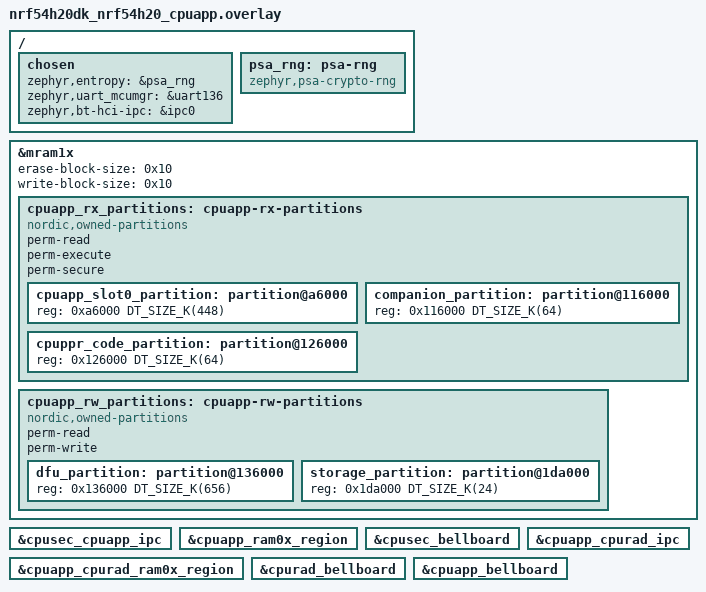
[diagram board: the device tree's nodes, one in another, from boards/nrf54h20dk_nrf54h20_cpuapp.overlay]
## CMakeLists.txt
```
#
# Copyright (c) 2023 Nordic Semiconductor ASA
#
# SPDX-License-Identifier: LicenseRef-Nordic-5-Clause
#

cmake_minimum_required(VERSION 3.13.1)

find_package(Zephyr REQUIRED HINTS $ENV{ZEPHYR_BASE})

project(suit_smp_transfer)

target_sources(app PRIVATE src/main.c)

# This project uses orginal sdk-zephyr C source code
target_include_directories(app PRIVATE $ENV{ZEPHYR_BASE}/samples/subsys/mgmt/mcumgr/smp_svr/src)
target_sources_ifdef(CONFIG_MCUMGR_TRANSPORT_BT app PRIVATE $ENV{ZEPHYR_BASE}/samples/subsys/mgmt/mcumgr/smp_svr/src/bluetooth.c)
```

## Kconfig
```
#
# Copyright (c) 2023 Nordic Semiconductor ASA
#
# SPDX-License-Identifier: LicenseRef-Nordic-5-Clause
#

config N_BLINKS
	int "Number of fast blinks"
	default 1

source "Kconfig.zephyr"
```

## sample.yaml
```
#
# Copyright (c) 2023 Nordic Semiconductor ASA
#
# SPDX-License-Identifier: LicenseRef-Nordic-5-Clause
#

sample:
  name: SUIT update through SMP sample
  description: Sample application that updates firmware using SUIT and SMP protocol
common:
  platform_allow: nrf54h20dk/nrf54h20/cpuapp
  build_only: true
  sysbuild: true
tests:
  sample.suit.smp_transfer:
    tags:
      - suit
      - ci_samples_suit
  sample.suit.smp_transfer.bt:
    extra_args:
      - FILE_SUFFIX=bt
    tags:
      - suit
      - bluetooth
      - ci_samples_suit
  sample.suit.smp_transfer.full_processing:
    extra_configs:
      - CONFIG_SUIT_DFU_CANDIDATE_PROCESSING_FULL=y
    tags:
      - suit
      - ci_samples_suit
  sample.suit.smp_transfer.full_processing.bt:
    extra_args:
      - FILE_SUFFIX=bt
    extra_configs:
      - CONFIG_SUIT_DFU_CANDIDATE_PROCESSING_FULL=y
    tags:
      - suit
      - bluetooth
      - ci_samples_suit
  sample.suit.smp_transfer.full_processing.extflash:
    extra_args:
      - EXTRA_DTC_OVERLAY_FILE="boards/nrf54h20dk_nrf54h20_cpuapp_extflash.overlay"
      - SB_CONFIG_SUIT_BUILD_FLASH_COMPANION=y
      # Workaround for sample.yaml - problems with strings. In the command line simply use:
      # -D'SB_CONFIG_SUIT_ENVELOPE_ROOT_TEMPLATE_FILENAME="root_with_binary_nordic_top_extflash.yaml.jinja2"'
      - SB_EXTRA_CONF_FILE="sysbuild_extflash_template.conf"
    extra_configs:
      - CONFIG_SUIT_ENVELOPE_TEMPLATE_FILENAME="app_envelope_extflash.yaml.jinja2"
      - CONFIG_SUIT_STREAM_SOURCE_FLASH=y
      - CONFIG_SUIT_DFU_CANDIDATE_PROCESSING_FULL=y
    tags:
      - suit
      - ci_samples_suit
  sample.suit.smp_transfer.recovery:
    extra_args:
      - FILE_SUFFIX=bt
      - SB_CONFIG_SUIT_BUILD_RECOVERY=y
    tags:
      - suit
      - bluetooth
      - ci_samples_suit
  sample.suit.smp_transfer.full_processing.extflash.bt:
    extra_args:
      - FILE_SUFFIX=bt
      - EXTRA_DTC_OVERLAY_FILE="boards/nrf54h20dk_nrf54h20_cpuapp_extflash.overlay"
      - SB_CONFIG_SUIT_BUILD_FLASH_COMPANION=y
      - SB_CONFIG_SUIT_BUILD_RECOVERY=y
      - recovery_TARGET_EXTRA_DTC_OVERLAY_FILE="boards/nrf54h20dk_nrf54h20_cpuapp_extflash.overlay"
      # Workaround for sample.yaml - problems with strings. In the command line simply use:
      # -D'SB_CONFIG_SUIT_ENVELOPE_ROOT_TEMPLATE_FILENAME="root_with_binary_nordic_top_extflash.yaml.jinja2"'
      - SB_EXTRA_CONF_FILE="sysbuild_extflash_template.conf"
      # Workaround for sample.yaml (part also in sysbuild.cmake), in the command line simply use:
      # -D'hci_ipc_CONFIG_SUIT_ENVELOPE_TEMPLATE_FILENAME="rad_envelope_extflash.yaml.jinja2"'
      - hci_ipc_TARGET_EXTRA_CONF_FILE="sysbuild/hci_ipc_extflash_template.conf"
    extra_configs:
      - CONFIG_SUIT_ENVELOPE_TEMPLATE_FILENAME="app_envelope_extflash.yaml.jinja2"
      - CONFIG_SUIT_STREAM_SOURCE_FLASH=y
      - CONFIG_SUIT_DFU_CANDIDATE_PROCESSING_FULL=y
    tags:
      - suit
      - bluetooth
      - ci_samples_suit
  sample.suit.smp_transfer.cache_push.extflash:
    extra_args:
      - EXTRA_DTC_OVERLAY_FILE="boards/nrf54h20dk_nrf54h20_cpuapp_extflash.overlay"
      - SUIT_DFU_CACHE_PARTITION_1_EB_SIZE=4096
      - SB_CONFIG_SUIT_BUILD_FLASH_COMPANION=y
      # Workaround for sample.yaml - problems with strings. In the command line simply use:
      # -D'SB_CONFIG_SUIT_ENVELOPE_ROOT_TEMPLATE_FILENAME="root_with_binary_nordic_top_extflash.yaml.jinja2"'
      - SB_EXTRA_CONF_FILE="sysbuild_extflash_template.conf"
    extra_configs:
      - CONFIG_SUIT_ENVELOPE_TEMPLATE_FILENAME="app_envelope_extflash.yaml.jinja2"
      - CONFIG_SUIT_DFU_CACHE_EXTRACT_IMAGE=y
      - CONFIG_SUIT_DFU_CANDIDATE_PROCESSING_PUSH_TO_CACHE=y
    tags:
      - suit
      - ci_samples_suit
  sample.suit.smp_transfer.cache_push.extflash.bt:
    extra_args:
      - FILE_SUFFIX=bt
      - EXTRA_DTC_OVERLAY_FILE="boards/nrf54h20dk_nrf54h20_cpuapp_extflash.overlay"
      - recovery_TARGET_EXTRA_DTC_OVERLAY_FILE="boards/nrf54h20dk_nrf54h20_cpuapp_extflash.overlay"
      - SUIT_DFU_CACHE_PARTITION_1_EB_SIZE=4096
      - SB_CONFIG_SUIT_BUILD_FLASH_COMPANION=y
      - SB_CONFIG_SUIT_BUILD_RECOVERY=y
      # Workaround for sample.yaml - problems with strings. In the command line simply use:
      # -D'SB_CONFIG_SUIT_ENVELOPE_ROOT_TEMPLATE_FILENAME="root_with_binary_nordic_top_extflash.yaml.jinja2"'
      - SB_EXTRA_CONF_FILE="sysbuild_extflash_template.conf"
      # Workaround for sample.yaml (part also in sysbuild.cmake), in the command line simply use:
      # -D'hci_ipc_CONFIG_SUIT_ENVELOPE_TEMPLATE_FILENAME="rad_envelope_extflash.yaml.jinja2"'
      - hci_ipc_TARGET_EXTRA_CONF_FILE="sysbuild/hci_ipc_extflash_template.conf"
      - hci_ipc_CONFIG_SUIT_DFU_CACHE_EXTRACT_IMAGE=y
    extra_configs:
      - CONFIG_SUIT_ENVELOPE_TEMPLATE_FILENAME="app_envelope_extflash.yaml.jinja2"
      - CONFIG_SUIT_DFU_CACHE_EXTRACT_IMAGE=y
      - CONFIG_SUIT_DFU_CANDIDATE_PROCESSING_PUSH_TO_CACHE=y
    tags:
      - suit
      - bluetooth
      - ci_samples_suit
```

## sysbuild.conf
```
#
# Copyright (c) 2024 Nordic Semiconductor ASA
#
# SPDX-License-Identifier: LicenseRef-Nordic-5-Clause
#

SB_CONFIG_SUIT_ENVELOPE=y
```

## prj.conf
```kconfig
#
# Copyright (c) 2023 Nordic Semiconductor ASA
#
# SPDX-License-Identifier: LicenseRef-Nordic-5-Clause
#

# Enable DK LED library
CONFIG_DK_LIBRARY=y

# Enable mcumgr
CONFIG_NET_BUF=y
CONFIG_ZCBOR=y
CONFIG_ZCBOR_CANONICAL=y
CONFIG_MCUMGR=y
CONFIG_MCUMGR_SMP_LEGACY_RC_BEHAVIOUR=y
CONFIG_CRC=y

# Enable SUIT services
CONFIG_SUIT=y
CONFIG_MGMT_SUITFU=y
CONFIG_FLASH=y

# Extended SUIT commands over USER group
CONFIG_MGMT_SUITFU_GRP_SUIT=y

# Enable bootloader identification within OS Management group
CONFIG_MCUMGR_GRP_OS=y
CONFIG_MCUMGR_GRP_OS_BOOTLOADER_INFO=y
CONFIG_MCUMGR_MGMT_NOTIFICATION_HOOKS=y
CONFIG_MCUMGR_GRP_OS_BOOTLOADER_INFO_HOOK=y

# For UART transport settings see: sysbuild/smp_transfer.conf
# For BLE transport settings see: sysbuild/smp_transfer_bt.conf
```

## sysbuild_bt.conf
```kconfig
#
# Copyright (c) 2024 Nordic Semiconductor ASA
#
# SPDX-License-Identifier: LicenseRef-Nordic-5-Clause
#

SB_CONFIG_SUIT_ENVELOPE=y
SB_CONFIG_NETCORE_HCI_IPC=y
```

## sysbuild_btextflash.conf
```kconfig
#
# Copyright (c) 2024 Nordic Semiconductor ASA
#
# SPDX-License-Identifier: LicenseRef-Nordic-5-Clause
#

SB_CONFIG_SUIT_ENVELOPE=y
SB_CONFIG_SUIT_BUILD_FLASH_COMPANION=y
SB_CONFIG_SUIT_ENVELOPE_ROOT_TEMPLATE="templates/extflash/root_with_binary_nordic_top.yaml.jinja2"
SB_CONFIG_NETCORE_HCI_IPC=y
```

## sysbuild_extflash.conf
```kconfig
#
# Copyright (c) 2024 Nordic Semiconductor ASA
#
# SPDX-License-Identifier: LicenseRef-Nordic-5-Clause
#

SB_CONFIG_SUIT_ENVELOPE=y
SB_CONFIG_SUIT_BUILD_FLASH_COMPANION=y
SB_CONFIG_SUIT_ENVELOPE_ROOT_TEMPLATE_FILENAME="root_with_binary_nordic_top_extflash.yaml.jinja2"
```

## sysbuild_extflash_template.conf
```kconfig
#
# Copyright (c) 2024 Nordic Semiconductor ASA
#
# SPDX-License-Identifier: LicenseRef-Nordic-5-Clause
#

SB_CONFIG_SUIT_ENVELOPE_ROOT_TEMPLATE_FILENAME="root_with_binary_nordic_top_extflash.yaml.jinja2"
```

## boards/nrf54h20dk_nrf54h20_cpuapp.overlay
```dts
/*
 * Copyright (c) 2023 Nordic Semiconductor ASA
 *
 * SPDX-License-Identifier: LicenseRef-Nordic-5-Clause
 */

/ {
	chosen {
		zephyr,entropy = &psa_rng;
		zephyr,uart_mcumgr = &uart136;
		zephyr,bt-hci-ipc = &ipc0;
	};

	psa_rng: psa-rng {
		compatible = "zephyr,psa-crypto-rng";
		status = "okay";
	};
};

/delete-node/ &cpuapp_rx_partitions;
/delete-node/ &cpuapp_rw_partitions;

&mram1x {
	erase-block-size = < 0x10 >;
	/* Hardcoded inside the soc_flash_nrf_mram.c (MRAM_WORD_SIZE) */
	write-block-size = < 0x10 >;

	cpuapp_rx_partitions: cpuapp-rx-partitions {
		compatible = "nordic,owned-partitions", "fixed-partitions";
		status = "okay";
		perm-read;
		perm-execute;
		perm-secure;
		#address-cells = <1>;
		#size-cells = <1>;

		cpuapp_slot0_partition: partition@a6000 {
			reg = <0xa6000 DT_SIZE_K(448)>;
		};

		companion_partition: partition@116000 {
			reg = <0x116000 DT_SIZE_K(64)>;
		};

		cpuppr_code_partition: partition@126000 {
			reg = <0x126000 DT_SIZE_K(64)>;
		};
	};

	cpuapp_rw_partitions: cpuapp-rw-partitions {
		compatible = "nordic,owned-partitions", "fixed-partitions";
		status = "okay";
		perm-read;
		perm-write;
		#address-cells = < 0x1 >;
		#size-cells = < 0x1 >;

		dfu_partition: partition@136000 {
			reg = < 0x136000 DT_SIZE_K(656) >;
		};

		storage_partition: partition@1da000 {
			reg = < 0x1da000 DT_SIZE_K(24) >;
		};
	};
};

&cpusec_cpuapp_ipc {
	status = "okay";
};

&cpuapp_ram0x_region {
	status = "okay";
};

&cpusec_bellboard {
	status = "okay";
};

ipc0: &cpuapp_cpurad_ipc {
	status = "okay";
};

&cpuapp_cpurad_ram0x_region {
	status = "okay";
};

&cpurad_bellboard {
	status = "okay";
};

&cpuapp_bellboard {
	status = "okay";
};
```

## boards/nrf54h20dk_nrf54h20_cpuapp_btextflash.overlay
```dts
/*
 * Copyright (c) 2024 Nordic Semiconductor ASA
 *
 * SPDX-License-Identifier: LicenseRef-Nordic-5-Clause
 */

#include "nrf54h20dk_nrf54h20_cpuapp_common.dtsi"

/ {
	chosen {
		extmem-device = &mx25uw63;
	};
};

&mx25uw63 {
	status = "okay";
	partitions {
		compatible = "fixed-partitions";
		#address-cells = <1>;
		#size-cells = <1>;

		dfu_cache_partition_1: partition@0 {
			reg = <0x0 DT_SIZE_K(1024)>;
		};
	};
};
```

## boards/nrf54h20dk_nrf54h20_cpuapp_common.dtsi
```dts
/*
 * Copyright (c) 2024 Nordic Semiconductor ASA
 *
 * SPDX-License-Identifier: LicenseRef-Nordic-5-Clause
 */

 #include "../sysbuild/nrf54h20dk_nrf54h20_memory_map.dtsi"

/ {
	chosen {
		zephyr,entropy = &psa_rng;
		zephyr,uart-mcumgr = &uart136;
		zephyr,bt-hci-ipc = &ipc0;
	};

	psa_rng: psa-rng {
		compatible = "zephyr,psa-crypto-rng";
		status = "okay";
	};
};

&cpusec_cpuapp_ipc {
	status = "okay";
};

&cpuapp_ram0x_region {
	status = "okay";
};

&cpusec_bellboard {
	status = "okay";
};

ipc0: &cpuapp_cpurad_ipc {
	status = "okay";
};

&cpurad_bellboard {
	status = "okay";
};

&cpuapp_bellboard {
	status = "okay";
};

&uart136 {
	/delete-property/ hw-flow-control;
};
```

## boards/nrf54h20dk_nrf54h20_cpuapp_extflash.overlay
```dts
/*
 * Copyright (c) 2024 Nordic Semiconductor ASA
 *
 * SPDX-License-Identifier: LicenseRef-Nordic-5-Clause
 */

/ {
	chosen {
		extmem-device = &mx25uw63;
	};
};

&mx25uw63 {
	status = "okay";
	partitions {
		compatible = "fixed-partitions";
		#address-cells = <1>;
		#size-cells = <1>;

		dfu_cache_partition_1: partition@0 {
			reg = <0x0 DT_SIZE_K(1024)>;
		};
	};
};

&cpuapp_rx_partitions {
	/delete-node/ partition@9d000;
	cpuapp_recovery_partition: partition@9d000 {
		reg = <0x9d000 DT_SIZE_K(84)>;
	};

	/delete-node/ partition@af000;
	cpuapp_recovery_rfu_partition: partition@b2000 {
		reg = <0xb2000 DT_SIZE_K(44)>;
	};

	/delete-node/ partition@bd000;
	cpuapp_slot0_partition: partition@bd000 {
		reg = <0xbd000 DT_SIZE_K(780)>;
	};
};

&cpuapp_rw_partitions {
	/delete-node/ partition@100000;
	dfu_partition: partition@180000 {
		reg = < 0x180000 DT_SIZE_K(396) >;
	};
};
```

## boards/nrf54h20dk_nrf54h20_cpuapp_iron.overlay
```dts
/*
 * Copyright (c) 2023 Nordic Semiconductor ASA
 *
 * SPDX-License-Identifier: LicenseRef-Nordic-5-Clause
 */

#include "nrf54h20dk_nrf54h20_cpuapp_common.dtsi"
```

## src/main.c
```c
/*
 * Copyright (c) 2023 Nordic Semiconductor ASA
 *
 * SPDX-License-Identifier: LicenseRef-Nordic-5-Clause
 */

#include <zephyr/kernel.h>
#include <dk_buttons_and_leds.h>
#ifdef CONFIG_MGMT_SUITFU
#include <suitfu_mgmt.h>
#endif /* CONFIG_MGMT_SUITFU */
#include <zephyr/storage/flash_map.h>
#include "common.h"

#ifdef CONFIG_SSF_SUIT_SERVICE_ENABLED
#include <sdfw/sdfw_services/suit_service.h>
#endif /* CONFIG_SSF_SUIT_SERVICE_ENABLED */

#define DFU_PARTITION_OFFSET  FIXED_PARTITION_OFFSET(dfu_partition)
#define DFU_PARTITION_SIZE    FIXED_PARTITION_SIZE(dfu_partition)
#define DFU_PARTITION_ADDRESS suit_plat_mem_nvm_ptr_get(DFU_PARTITION_OFFSET)

int main(void)
{
	int ret = dk_leds_init();

	if (ret) {
		printk("Cannot init LEDs (err: %d)\r\n", ret);
	}

	printk("Hello world from %s blinks: %d, BUILD: %s %s\r\n", CONFIG_BOARD, CONFIG_N_BLINKS,
	       __DATE__, __TIME__);

	if (IS_ENABLED(CONFIG_MCUMGR_TRANSPORT_BT)) {
		start_smp_bluetooth_adverts();
	}

	while (1) {
		for (int i = 0; i < CONFIG_N_BLINKS; i++) {
			dk_set_led_on(DK_LED1);
			k_msleep(250);
			dk_set_led_off(DK_LED1);
			k_msleep(250);
		}

		k_msleep(5000);
	}

	return 0;
}
```
